# MKL81Z7 register map
Vendor: Freescale Semiconductor, Inc.; Series: Kinetis_L; File version: 1.6
CPU: CM0PLUS r0p0, little endian, no MPU, no FPU, VTOR, 2 interrupt priority bits
Registers are 32-bit, read-write, reset 0x0 unless marked. A register's access mark holds for its fields unless they carry their own. Offsets are from the block's base; [hi:lo] are bit positions; {n}, {i} and the like mark numbered series; 'fields as' and 'values as' point back to an identical list.

## VREF — Voltage Reference
Base 0x40074000; register names take the prefix VREF_
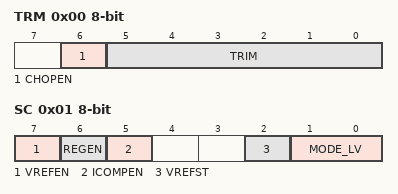
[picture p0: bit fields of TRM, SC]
0x00 TRM 8-bit (reset mask 0x40) — VREF Trim Register
  [6] CHOPEN — Chop oscillator enable. When set, internal chopping operation is enabled and the internal analog offset will be minimized.
    0=Chop oscillator is disabled; 1=Chop oscillator is enabled
  [5:0] TRIM — Trim bits
    0=Min; 63=Max
0x01 SC 8-bit — VREF Status and Control Register
  [7] VREFEN — Internal Voltage Reference enable
    0=The module is disabled; 1=The module is enabled
  [6] REGEN — Regulator enable
    0=Internal 1.75 V regulator is disabled; 1=Internal 1.75 V regulator is enabled
  [5] ICOMPEN — Second order curvature compensation enable
    0=Disabled; 1=Enabled
  [2] VREFST ro — Internal Voltage Reference stable
    0=The module is disabled or not stable; 1=The module is stable
  [1:0] MODE_LV — Buffer Mode selection
    0=Bandgap on only, for stabilization and startup; 1=High power buffer mode enabled; 2=Low-power buffer mode enabled

## LLWU — Low leakage wakeup unit
Base 0x4007C000; register names take the prefix LLWU_
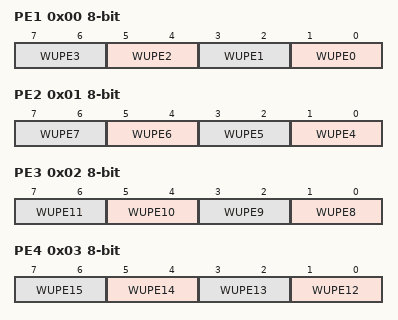
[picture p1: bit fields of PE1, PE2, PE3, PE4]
0x00 PE1 8-bit — LLWU Pin Enable 1 register
  [all] fields
    0=External input pin disabled as wakeup input; 1=External input pin enabled with rising edge detection; 2=External input pin enabled with falling edge detection; 3=External input pin enabled with any change detection
  [2n+1:2n] WUPE{n} (n=0..3) — Wakeup Pin Enable For LLWU_P{n}
0x01 PE2 8-bit — LLWU Pin Enable 2 register
  [all] fields
    values as the fields of PE1
  [2n-7:2n-8] WUPE{n} (n=4..7) — Wakeup Pin Enable For LLWU_P{n}
0x02 PE3 8-bit — LLWU Pin Enable 3 register
  [all] fields
    values as the fields of PE1
  [2n-15:2n-16] WUPE{n} (n=8..11) — Wakeup Pin Enable For LLWU_P{n}
0x03 PE4 8-bit — LLWU Pin Enable 4 register
  [all] fields
    values as the fields of PE1
  [2n-23:2n-24] WUPE{n} (n=12..15) — Wakeup Pin Enable For LLWU_P{n}
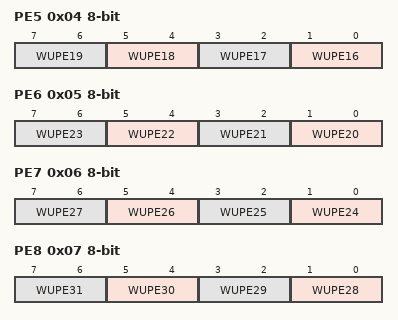
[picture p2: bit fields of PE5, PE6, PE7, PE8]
0x04 PE5 8-bit — LLWU Pin Enable 5 register
  [all] fields
    values as the fields of PE1
  [2n-31:2n-32] WUPE{n} (n=16..19) — Wakeup Pin Enable For LLWU_P{n}
0x05 PE6 8-bit — LLWU Pin Enable 6 register
  [all] fields
    values as the fields of PE1
  [2n-39:2n-40] WUPE{n} (n=20..23) — Wakeup Pin Enable For LLWU_P{n}
0x06 PE7 8-bit — LLWU Pin Enable 7 register
  [all] fields
    values as the fields of PE1
  [2n-47:2n-48] WUPE{n} (n=24..27) — Wakeup Pin Enable For LLWU_P{n}
0x07 PE8 8-bit — LLWU Pin Enable 8 register
  [all] fields
    values as the fields of PE1
  [2n-55:2n-56] WUPE{n} (n=28..31) — Wakeup Pin Enable For LLWU_P{n}
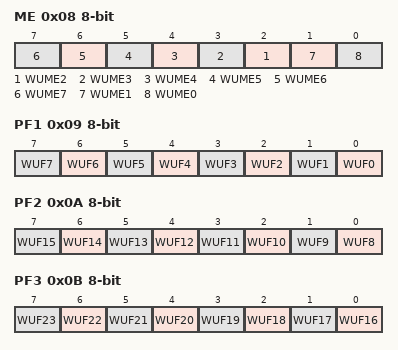
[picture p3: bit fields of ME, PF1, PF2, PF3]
0x08 ME 8-bit — LLWU Module Enable register
  [all] fields
    0=Internal module flag not used as wakeup source; 1=Internal module flag used as wakeup source
  [n] WUME{n} (n=2..7) — Wakeup Module Enable For Module {n}
  [1] WUME1 — Wakeup Module Enable for Module 1
  [0] WUME0 — Wakeup Module Enable For Module 0
0x09 PF1 8-bit — LLWU Pin Flag 1 register
  [n] WUF{n} (n=0..7) — Wakeup Flag For LLWU_P{n}
    0=LLWU_P{n} input was not a wakeup source; 1=LLWU_P{n} input was a wakeup source
0x0A PF2 8-bit — LLWU Pin Flag 2 register
  [n-8] WUF{n} (n=8..15) — Wakeup Flag For LLWU_P{n}
    values as PF1.WUF0
0x0B PF3 8-bit — LLWU Pin Flag 3 register
  [n-16] WUF{n} (n=16..23) — Wakeup Flag For LLWU_P{n}
    values as PF1.WUF0
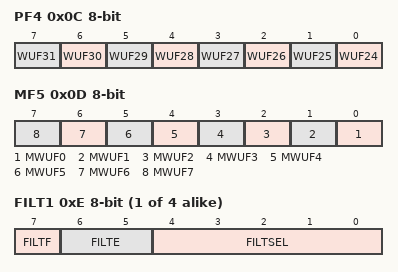
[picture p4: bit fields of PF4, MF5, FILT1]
0x0C PF4 8-bit — LLWU Pin Flag 4 register
  [n-24] WUF{n} (n=24..31) — Wakeup Flag For LLWU_P{n}
    values as PF1.WUF0
0x0D MF5 8-bit ro — LLWU Module Flag 5 register
  [n] MWUF{n} (n=0..7) — Wakeup flag For module {n}
    0=Module {n} input was not a wakeup source; 1=Module {n} input was a wakeup source
{0xD+i} FILT{i} 8-bit (i=1..4) — LLWU Pin Filter {i} register
  [7] FILTF — Filter Detect Flag
    0=Pin Filter {i} was not a wakeup source; 1=Pin Filter {i} was a wakeup source
  [6:5] FILTE — Digital Filter On External Pin
    0=Filter disabled; 1=Filter posedge detect enabled; 2=Filter negedge detect enabled; 3=Filter any edge detect enabled
  [4:0] FILTSEL — Filter Pin Select
    0=Select LLWU_P0 for filter; 31=Select LLWU_P31 for filter
